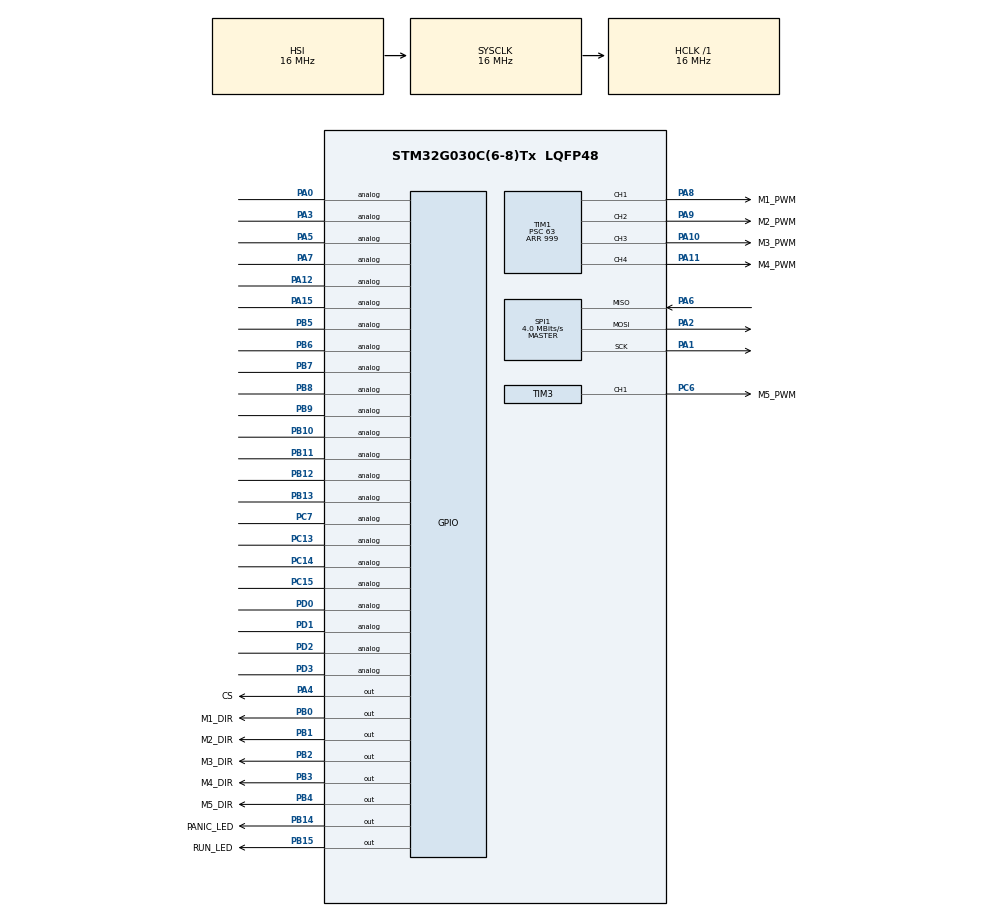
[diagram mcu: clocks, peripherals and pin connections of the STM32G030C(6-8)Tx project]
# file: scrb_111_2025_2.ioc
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Mcu.Family=STM32G0
Mcu.Name=STM32G030C(6-8)Tx
Mcu.Package=LQFP48
PA0.Signal=GPIO_Analog
PA1.Mode=Full_Duplex_Master
PA1.Signal=SPI1_SCK
PA10.GPIO_Label=M3_PWM
PA10.Signal=S_TIM1_CH3
PA11\ [PA9].GPIO_Label=M4_PWM
PA11\ [PA9].Signal=S_TIM1_CH4
PA12\ [PA10].Signal=GPIO_Analog
PA13.Mode=Serial_Wire
PA13.Signal=SYS_SWDIO
PA14-BOOT0.Mode=Serial_Wire
PA14-BOOT0.Signal=SYS_SWCLK
PA15.Signal=GPIO_Analog
PA2.Mode=Full_Duplex_Master
PA2.Signal=SPI1_MOSI
PA3.Signal=GPIO_Analog
PA4.GPIO_Label=CS
PA4.PinState=GPIO_PIN_SET
PA4.Signal=GPIO_Output
PA5.Signal=GPIO_Analog
PA6.Mode=Full_Duplex_Master
PA6.Signal=SPI1_MISO
PA7.Signal=GPIO_Analog
PA8.GPIO_Label=M1_PWM
PA8.Signal=S_TIM1_CH1
PA9.GPIO_Label=M2_PWM
PA9.Signal=S_TIM1_CH2
PB0.GPIO_Label=M1_DIR
PB0.Signal=GPIO_Output
PB1.GPIO_Label=M2_DIR
PB1.Signal=GPIO_Output
PB10.Signal=GPIO_Analog
PB11.Signal=GPIO_Analog
PB12.Signal=GPIO_Analog
PB13.Signal=GPIO_Analog
PB14.GPIO_Label=PANIC_LED
PB14.GPIO_ModeDefaultOutputPP=GPIO_MODE_OUTPUT_OD
PB14.GPIO_PuPd=GPIO_NOPULL
PB14.GPIO_Speed=GPIO_SPEED_FREQ_HIGH
PB14.PinState=GPIO_PIN_RESET
PB14.Signal=GPIO_Output
PB15.GPIO_Label=RUN_LED
PB15.GPIO_ModeDefaultOutputPP=GPIO_MODE_OUTPUT_OD
PB15.GPIO_PuPd=GPIO_NOPULL
PB15.GPIO_Speed=GPIO_SPEED_FREQ_HIGH
PB15.PinState=GPIO_PIN_RESET
PB15.Signal=GPIO_Output
PB2.GPIO_Label=M3_DIR
PB2.Signal=GPIO_Output
PB3.GPIO_Label=M4_DIR
PB3.Signal=GPIO_Output
PB4.GPIO_Label=M5_DIR
PB4.Signal=GPIO_Output
PB5.Signal=GPIO_Analog
PB6.Signal=GPIO_Analog
PB7.Signal=GPIO_Analog
PB8.Signal=GPIO_Analog
PB9.Signal=GPIO_Analog
PC13.Signal=GPIO_Analog
PC14-OSC32_IN\ (PC14).Signal=GPIO_Analog
PC15-OSC32_OUT\ (PC15).Signal=GPIO_Analog
PC6.GPIO_Label=M5_PWM
PC6.Signal=S_TIM3_CH1
PC7.Signal=GPIO_Analog
PD0.Signal=GPIO_Analog
PD1.Signal=GPIO_Analog
PD2.Signal=GPIO_Analog
PD3.Signal=GPIO_Analog
PF0-OSC_IN\ (PF0).Mode=HSE-External-Oscillator
PF0-OSC_IN\ (PF0).Signal=RCC_OSC_IN
PF1-OSC_OUT\ (PF1).Mode=HSE-External-Oscillator
PF1-OSC_OUT\ (PF1).Signal=RCC_OSC_OUT
ProjectManager.HeapSize=0x200
ProjectManager.StackSize=0x400
ProjectManager.TargetToolchain=STM32CubeIDE
RCC.ADCFreq_Value=16000000
RCC.AHBFreq_Value=16000000
RCC.CortexFreq_Value=16000000
RCC.EXTERNAL_CLOCK_VALUE=12288000
RCC.HCLKFreq_Value=16000000
RCC.HSE_VALUE=16000000
RCC.HSI_VALUE=16000000
RCC.LSE_VALUE=32768
RCC.SYSCLKFreq_VALUE=16000000
RCC.VCOOutputFreq_Value=128000000
SH.S_TIM1_CH1.0=TIM1_CH1,PWM Generation1 CH1
SH.S_TIM1_CH2.0=TIM1_CH2,PWM Generation2 CH2
SH.S_TIM1_CH3.0=TIM1_CH3,PWM Generation3 CH3
SH.S_TIM1_CH4.0=TIM1_CH4,PWM Generation4 CH4
SH.S_TIM3_CH1.0=TIM3_CH1,PWM Generation1 CH1
SPI1.BaudRatePrescaler=SPI_BAUDRATEPRESCALER_4
SPI1.CalculateBaudRate=4.0 MBits/s
SPI1.Direction=SPI_DIRECTION_2LINES
SPI1.Mode=SPI_MODE_MASTER
SPI1.VirtualType=VM_MASTER
TIM1.AutomaticOutput=TIM_AUTOMATICOUTPUT_ENABLE
TIM1.Channel-PWM\ Generation1\ CH1=TIM_CHANNEL_1
TIM1.Channel-PWM\ Generation2\ CH2=TIM_CHANNEL_2
TIM1.Channel-PWM\ Generation3\ CH3=TIM_CHANNEL_3
TIM1.Channel-PWM\ Generation4\ CH4=TIM_CHANNEL_4
TIM1.Period=999
TIM1.Prescaler=63
TIM3.Channel-PWM\ Generation1\ CH1=TIM_CHANNEL_1
TIM3.Period=999
TIM3.Prescaler=63
VP_IWDG_VS_IWDG.Mode=IWDG_Activate
VP_TIM1_VS_ClockSourceINT.Mode=Internal
VP_TIM3_VS_ClockSourceINT.Mode=Internal
board=custom

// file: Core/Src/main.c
/* USER CODE BEGIN Header */
/**
  ******************************************************************************
  * @file           : main.c
  * @brief          : Main program body
  ******************************************************************************
  * @attention
  *
  * Copyright (c) 2026 STMicroelectronics.
  * All rights reserved.
  *
  * This software is licensed under terms that can be found in the LICENSE file
  * in the root directory of this software component.
  * If no LICENSE file comes with this software, it is provided AS-IS.
  *
  ******************************************************************************
  */
/* USER CODE END Header */
#include "main.h"
#include "mcp25625.h"
#include "protocol.h"
#include <string.h>
#include <math.h>

IWDG_HandleTypeDef hiwdg;

SPI_HandleTypeDef hspi1;

TIM_HandleTypeDef htim1;
TIM_HandleTypeDef htim3;

void SystemClock_Config(void);
static void MX_GPIO_Init(void);
static void MX_IWDG_Init(void);
static void MX_SPI1_Init(void);
static void MX_TIM1_Init(void);
static void MX_TIM3_Init(void);

int main(void)
{

  /* MCU Configuration--------------------------------------------------------*/

  /* Reset of all peripherals, Initializes the Flash interface and the Systick. */
  HAL_Init();

  /* Configure the system clock */
  SystemClock_Config();

  /* Initialize all configured peripherals */
  MX_GPIO_Init();
  MX_IWDG_Init();
  MX_SPI1_Init();
  MX_TIM1_Init();
  MX_TIM3_Init();
  /* USER CODE BEGIN 2 */

  // starting up the timers for the pwm for each motor
  CanFrame frame = {0};

  start_motors();

  MCP_attach(&hspi1, CS_GPIO_Port, CS_Pin);
  if (!MCP_init()) {
      Error_Handler();
  }

  /* USER CODE END 2 */

  /* Infinite loop */
  /* USER CODE BEGIN WHILE */
  while (1)   {

      HAL_IWDG_Refresh(&hiwdg);
      HAL_GPIO_WritePin(GPIOB, PANIC_LED_Pin, GPIO_PIN_SET);

      if (MCP_receive_frame(&frame))
      {
          uint8_t device_id   = (frame.id >> 1)  & 0x3F;
          uint8_t instruction = (frame.id >> 7)  & 0xFF;
          uint8_t severity    = (frame.id >> 15) & 0x03;

          if (device_id == BOARD_DEVICE_ID && severity == ctrl_id_type)
          {
              if (instruction == force_stop_id_bit) {
                  stop_motors();

                  CanFrame hb_frame = {0};
                  hb_frame.id  = JETSON_MAKE_ID(status_id_type, error_id_bit);
                  hb_frame.dlc = 4;
                  hb_frame.data[0] = 'E';
                  hb_frame.data[1] = '0';
                  hb_frame.data[2] = '7';
                  hb_frame.data[3] = '0';

                  while (1) {
                      HAL_IWDG_Refresh(&hiwdg);
                      MCP_send_frame(&hb_frame);
                      HAL_Delay(100);

                      CanFrame rx = {0};
                      if (MCP_receive_frame(&rx)) {
                          uint8_t rx_dev = (rx.id >> 1)  & 0x3F;
                          uint8_t rx_ins = (rx.id >> 7)  & 0xFF;
                          uint8_t rx_sev = (rx.id >> 15) & 0x03;
                          if (rx_dev == BOARD_DEVICE_ID
                              && rx_sev == ctrl_id_type
                              && rx_ins == resume_id_bit) {
                              start_motors();
                              break;
                          }
                      }
                  }
              }
              else if (instruction == motor_1_id_bit) {
                  float rads;
                  memcpy(&rads, &frame.data[0], 4);
                  uint16_t duty = (fabsf(rads) / MAX_RADS) * htim1.Init.Period;
                  if (duty > htim1.Init.Period) duty = htim1.Init.Period;
                  __HAL_TIM_SET_COMPARE(&htim1, TIM_CHANNEL_1, duty);
                  HAL_GPIO_WritePin(GPIOB, M1_DIR_Pin,
                      rads >= 0.0f ? GPIO_PIN_SET : GPIO_PIN_RESET);

              }
              else if (instruction == motor_2_id_bit) {
                  float rads;
                  memcpy(&rads, &frame.data[0], 4);
                  uint16_t duty = (fabsf(rads) / MAX_RADS) * htim1.Init.Period;
                  if (duty > htim1.Init.Period) duty = htim1.Init.Period;
                  __HAL_TIM_SET_COMPARE(&htim1, TIM_CHANNEL_2, duty);
                  HAL_GPIO_WritePin(GPIOB, M2_DIR_Pin,
                      rads >= 0.0f ? GPIO_PIN_SET : GPIO_PIN_RESET);
              }
              else if (instruction == motor_3_id_bit) {
                  float rads;
                  memcpy(&rads, &frame.data[0], 4);
                  uint16_t duty = (fabsf(rads) / MAX_RADS) * htim1.Init.Period;
                  if (duty > htim1.Init.Period) duty = htim1.Init.Period;
                  __HAL_TIM_SET_COMPARE(&htim1, TIM_CHANNEL_3, duty);
                  HAL_GPIO_WritePin(GPIOB, M3_DIR_Pin,
                      rads >= 0.0f ? GPIO_PIN_SET : GPIO_PIN_RESET);
              }
              else if (instruction == motor_4_id_bit) {
                  float rads;
                  memcpy(&rads, &frame.data[0], 4);
                  uint16_t duty = (fabsf(rads) / MAX_RADS) * htim1.Init.Period;
                  if (duty > htim1.Init.Period) duty = htim1.Init.Period;
                  __HAL_TIM_SET_COMPARE(&htim1, TIM_CHANNEL_4, duty);
                  HAL_GPIO_WritePin(GPIOB, M4_DIR_Pin,
                      rads >= 0.0f ? GPIO_PIN_SET : GPIO_PIN_RESET);
              }
              else if (instruction == motor_5_id_bit) {
                  float rads;
                  memcpy(&rads, &frame.data[0], 4);
                  uint16_t duty = (fabsf(rads) / MAX_RADS) * htim3.Init.Period;
                  if (duty > htim3.Init.Period) duty = htim3.Init.Period;
                  __HAL_TIM_SET_COMPARE(&htim3, TIM_CHANNEL_1, duty);
                  HAL_GPIO_WritePin(GPIOB, M5_DIR_Pin,
                      rads >= 0.0f ? GPIO_PIN_SET : GPIO_PIN_RESET);
              }

          }
      }

      uint8_t eflg = MCP_read_eflg();

      if (eflg & (MCP_EFLG_RX1OVR | MCP_EFLG_RX0OVR)) {

          MCP_clear_rx_overflow();

          HAL_GPIO_WritePin(GPIOB, PANIC_LED_Pin, GPIO_PIN_RESET);

      }

      if (eflg & MCP_EFLG_TXBO) {

          HAL_GPIO_WritePin(GPIOB, PANIC_LED_Pin, GPIO_PIN_RESET);

      }

  }
  /* USER CODE END 3 */
}

void SystemClock_Config(void)
{
  RCC_OscInitTypeDef RCC_OscInitStruct = {0};
  RCC_ClkInitTypeDef RCC_ClkInitStruct = {0};

  /** Configure the main internal regulator output voltage
  */
  HAL_PWREx_ControlVoltageScaling(PWR_REGULATOR_VOLTAGE_SCALE1);

  /** Initializes the RCC Oscillators according to the specified parameters
  * in the RCC_OscInitTypeDef structure.
  */
  RCC_OscInitStruct.OscillatorType = RCC_OSCILLATORTYPE_HSI|RCC_OSCILLATORTYPE_LSI;
  RCC_OscInitStruct.HSIState = RCC_HSI_ON;
  RCC_OscInitStruct.HSIDiv = RCC_HSI_DIV1;
  RCC_OscInitStruct.HSICalibrationValue = RCC_HSICALIBRATION_DEFAULT;
  RCC_OscInitStruct.LSIState = RCC_LSI_ON;
  RCC_OscInitStruct.PLL.PLLState = RCC_PLL_NONE;
  if (HAL_RCC_OscConfig(&RCC_OscInitStruct) != HAL_OK)
  {
    Error_Handler();
  }

  /** Initializes the CPU, AHB and APB buses clocks
  */
  RCC_ClkInitStruct.ClockType = RCC_CLOCKTYPE_HCLK|RCC_CLOCKTYPE_SYSCLK
                              |RCC_CLOCKTYPE_PCLK1;
  RCC_ClkInitStruct.SYSCLKSource = RCC_SYSCLKSOURCE_HSI;
  RCC_ClkInitStruct.AHBCLKDivider = RCC_SYSCLK_DIV1;
  RCC_ClkInitStruct.APB1CLKDivider = RCC_HCLK_DIV1;

  if (HAL_RCC_ClockConfig(&RCC_ClkInitStruct, FLASH_LATENCY_0) != HAL_OK)
  {
    Error_Handler();
  }
}

static void MX_IWDG_Init(void)
{

  hiwdg.Instance = IWDG;
  hiwdg.Init.Prescaler = IWDG_PRESCALER_4;
  hiwdg.Init.Window = 4095;
  hiwdg.Init.Reload = 4095;
  if (HAL_IWDG_Init(&hiwdg) != HAL_OK)
  {
    Error_Handler();
  }

}

static void MX_SPI1_Init(void)
{

  /* SPI1 parameter configuration*/
  hspi1.Instance = SPI1;
  hspi1.Init.Mode = SPI_MODE_MASTER;
  hspi1.Init.Direction = SPI_DIRECTION_2LINES;
  hspi1.Init.DataSize = SPI_DATASIZE_8BIT;
  hspi1.Init.CLKPolarity = SPI_POLARITY_LOW;
  hspi1.Init.CLKPhase = SPI_PHASE_1EDGE;
  hspi1.Init.NSS = SPI_NSS_SOFT;
  hspi1.Init.BaudRatePrescaler = SPI_BAUDRATEPRESCALER_4;
  hspi1.Init.FirstBit = SPI_FIRSTBIT_MSB;
  hspi1.Init.TIMode = SPI_TIMODE_DISABLE;
  hspi1.Init.CRCCalculation = SPI_CRCCALCULATION_DISABLE;
  hspi1.Init.CRCPolynomial = 7;
  hspi1.Init.CRCLength = SPI_CRC_LENGTH_DATASIZE;
  hspi1.Init.NSSPMode = SPI_NSS_PULSE_ENABLE;
  if (HAL_SPI_Init(&hspi1) != HAL_OK)
  {
    Error_Handler();
  }

}

static void MX_TIM1_Init(void)
{

  TIM_ClockConfigTypeDef sClockSourceConfig = {0};
  TIM_MasterConfigTypeDef sMasterConfig = {0};
  TIM_OC_InitTypeDef sConfigOC = {0};
  TIM_BreakDeadTimeConfigTypeDef sBreakDeadTimeConfig = {0};

  htim1.Instance = TIM1;
  htim1.Init.Prescaler = 1;
  htim1.Init.CounterMode = TIM_COUNTERMODE_UP;
  htim1.Init.Period = 799;
  htim1.Init.ClockDivision = TIM_CLOCKDIVISION_DIV1;
  htim1.Init.RepetitionCounter = 0;
  htim1.Init.AutoReloadPreload = TIM_AUTORELOAD_PRELOAD_DISABLE;
  if (HAL_TIM_Base_Init(&htim1) != HAL_OK)
  {
    Error_Handler();
  }
  sClockSourceConfig.ClockSource = TIM_CLOCKSOURCE_INTERNAL;
  if (HAL_TIM_ConfigClockSource(&htim1, &sClockSourceConfig) != HAL_OK)
  {
    Error_Handler();
  }
  if (HAL_TIM_PWM_Init(&htim1) != HAL_OK)
  {
    Error_Handler();
  }
  sMasterConfig.MasterOutputTrigger = TIM_TRGO_RESET;
  sMasterConfig.MasterOutputTrigger2 = TIM_TRGO2_RESET;
  sMasterConfig.MasterSlaveMode = TIM_MASTERSLAVEMODE_DISABLE;
  if (HAL_TIMEx_MasterConfigSynchronization(&htim1, &sMasterConfig) != HAL_OK)
  {
    Error_Handler();
  }
  sConfigOC.OCMode = TIM_OCMODE_PWM1;
  sConfigOC.Pulse = 0;
  sConfigOC.OCPolarity = TIM_OCPOLARITY_HIGH;
  sConfigOC.OCNPolarity = TIM_OCNPOLARITY_HIGH;
  sConfigOC.OCFastMode = TIM_OCFAST_DISABLE;
  sConfigOC.OCIdleState = TIM_OCIDLESTATE_RESET;
  sConfigOC.OCNIdleState = TIM_OCNIDLESTATE_RESET;
  if (HAL_TIM_PWM_ConfigChannel(&htim1, &sConfigOC, TIM_CHANNEL_1) != HAL_OK)
  {
    Error_Handler();
  }
  if (HAL_TIM_PWM_ConfigChannel(&htim1, &sConfigOC, TIM_CHANNEL_2) != HAL_OK)
  {
    Error_Handler();
  }
  if (HAL_TIM_PWM_ConfigChannel(&htim1, &sConfigOC, TIM_CHANNEL_3) != HAL_OK)
  {
    Error_Handler();
  }
  if (HAL_TIM_PWM_ConfigChannel(&htim1, &sConfigOC, TIM_CHANNEL_4) != HAL_OK)
  {
    Error_Handler();
  }
  sBreakDeadTimeConfig.OffStateRunMode = TIM_OSSR_DISABLE;
  sBreakDeadTimeConfig.OffStateIDLEMode = TIM_OSSI_DISABLE;
  sBreakDeadTimeConfig.LockLevel = TIM_LOCKLEVEL_OFF;
  sBreakDeadTimeConfig.DeadTime = 0;
  sBreakDeadTimeConfig.BreakState = TIM_BREAK_DISABLE;
  sBreakDeadTimeConfig.BreakPolarity = TIM_BREAKPOLARITY_HIGH;
  sBreakDeadTimeConfig.BreakFilter = 0;
  sBreakDeadTimeConfig.BreakAFMode = TIM_BREAK_AFMODE_INPUT;
  sBreakDeadTimeConfig.Break2State = TIM_BREAK2_DISABLE;
  sBreakDeadTimeConfig.Break2Polarity = TIM_BREAK2POLARITY_HIGH;
  sBreakDeadTimeConfig.Break2Filter = 0;
  sBreakDeadTimeConfig.Break2AFMode = TIM_BREAK_AFMODE_INPUT;
  sBreakDeadTimeConfig.AutomaticOutput = TIM_AUTOMATICOUTPUT_ENABLE;
  if (HAL_TIMEx_ConfigBreakDeadTime(&htim1, &sBreakDeadTimeConfig) != HAL_OK)
  {
    Error_Handler();
  }
  HAL_TIM_MspPostInit(&htim1);

}

static void MX_TIM3_Init(void)
{

  TIM_ClockConfigTypeDef sClockSourceConfig = {0};
  TIM_MasterConfigTypeDef sMasterConfig = {0};
  TIM_OC_InitTypeDef sConfigOC = {0};

  htim3.Instance = TIM3;
  htim3.Init.Prescaler = 1;
  htim3.Init.CounterMode = TIM_COUNTERMODE_UP;
  htim3.Init.Period = 799;
  htim3.Init.ClockDivision = TIM_CLOCKDIVISION_DIV1;
  htim3.Init.AutoReloadPreload = TIM_AUTORELOAD_PRELOAD_DISABLE;
  if (HAL_TIM_Base_Init(&htim3) != HAL_OK)
  {
    Error_Handler();
  }
  sClockSourceConfig.ClockSource = TIM_CLOCKSOURCE_INTERNAL;
  if (HAL_TIM_ConfigClockSource(&htim3, &sClockSourceConfig) != HAL_OK)
  {
    Error_Handler();
  }
  if (HAL_TIM_PWM_Init(&htim3) != HAL_OK)
  {
    Error_Handler();
  }
  sMasterConfig.MasterOutputTrigger = TIM_TRGO_RESET;
  sMasterConfig.MasterSlaveMode = TIM_MASTERSLAVEMODE_DISABLE;
  if (HAL_TIMEx_MasterConfigSynchronization(&htim3, &sMasterConfig) != HAL_OK)
  {
    Error_Handler();
  }
  sConfigOC.OCMode = TIM_OCMODE_PWM1;
  sConfigOC.Pulse = 0;
  sConfigOC.OCPolarity = TIM_OCPOLARITY_HIGH;
  sConfigOC.OCFastMode = TIM_OCFAST_DISABLE;
  if (HAL_TIM_PWM_ConfigChannel(&htim3, &sConfigOC, TIM_CHANNEL_1) != HAL_OK)
  {
    Error_Handler();
  }
  HAL_TIM_MspPostInit(&htim3);

}

static void MX_GPIO_Init(void)
{
  GPIO_InitTypeDef GPIO_InitStruct = {0};

  /* GPIO Ports Clock Enable */
  __HAL_RCC_GPIOC_CLK_ENABLE();
  __HAL_RCC_GPIOF_CLK_ENABLE();
  __HAL_RCC_GPIOA_CLK_ENABLE();
  __HAL_RCC_GPIOB_CLK_ENABLE();
  __HAL_RCC_GPIOD_CLK_ENABLE();

  /*Configure GPIO pin Output Level */
  HAL_GPIO_WritePin(CS_GPIO_Port, CS_Pin, GPIO_PIN_SET);

  /*Configure GPIO pin Output Level */
  HAL_GPIO_WritePin(GPIOB, M1_DIR_Pin|M2_DIR_Pin|M3_DIR_Pin|PANIC_LED_Pin
                          |RUN_LED_Pin|M4_DIR_Pin|M5_DIR_Pin, GPIO_PIN_RESET);

  /*Configure GPIO pins : PC13 PC14 PC15 PC7 */
  GPIO_InitStruct.Pin = GPIO_PIN_13|GPIO_PIN_14|GPIO_PIN_15|GPIO_PIN_7;
  GPIO_InitStruct.Mode = GPIO_MODE_ANALOG;
  GPIO_InitStruct.Pull = GPIO_NOPULL;
  HAL_GPIO_Init(GPIOC, &GPIO_InitStruct);

  /*Configure GPIO pins : PA0 PA3 PA5 PA7
                           PA12 PA15 */
  GPIO_InitStruct.Pin = GPIO_PIN_0|GPIO_PIN_3|GPIO_PIN_5|GPIO_PIN_7
                          |GPIO_PIN_12|GPIO_PIN_15;
  GPIO_InitStruct.Mode = GPIO_MODE_ANALOG;
  GPIO_InitStruct.Pull = GPIO_NOPULL;
  HAL_GPIO_Init(GPIOA, &GPIO_InitStruct);

  /*Configure GPIO pin : CS_Pin */
  GPIO_InitStruct.Pin = CS_Pin;
  GPIO_InitStruct.Mode = GPIO_MODE_OUTPUT_PP;
  GPIO_InitStruct.Pull = GPIO_NOPULL;
  GPIO_InitStruct.Speed = GPIO_SPEED_FREQ_LOW;
  HAL_GPIO_Init(CS_GPIO_Port, &GPIO_InitStruct);

  /*Configure GPIO pins : M1_DIR_Pin M2_DIR_Pin M3_DIR_Pin M4_DIR_Pin
                           M5_DIR_Pin */
  GPIO_InitStruct.Pin = M1_DIR_Pin|M2_DIR_Pin|M3_DIR_Pin|M4_DIR_Pin
                          |M5_DIR_Pin;
  GPIO_InitStruct.Mode = GPIO_MODE_OUTPUT_PP;
  GPIO_InitStruct.Pull = GPIO_NOPULL;
  GPIO_InitStruct.Speed = GPIO_SPEED_FREQ_LOW;
  HAL_GPIO_Init(GPIOB, &GPIO_InitStruct);

  /*Configure GPIO pins : PB10 PB11 PB12 PB13
                           PB5 PB6 PB7 PB8
                           PB9 */
  GPIO_InitStruct.Pin = GPIO_PIN_10|GPIO_PIN_11|GPIO_PIN_12|GPIO_PIN_13
                          |GPIO_PIN_5|GPIO_PIN_6|GPIO_PIN_7|GPIO_PIN_8
                          |GPIO_PIN_9;
  GPIO_InitStruct.Mode = GPIO_MODE_ANALOG;
  GPIO_InitStruct.Pull = GPIO_NOPULL;
  HAL_GPIO_Init(GPIOB, &GPIO_InitStruct);

  /*Configure GPIO pins : PANIC_LED_Pin RUN_LED_Pin */
  GPIO_InitStruct.Pin = PANIC_LED_Pin|RUN_LED_Pin;
  GPIO_InitStruct.Mode = GPIO_MODE_OUTPUT_OD;
  GPIO_InitStruct.Pull = GPIO_NOPULL;
  GPIO_InitStruct.Speed = GPIO_SPEED_FREQ_HIGH;
  HAL_GPIO_Init(GPIOB, &GPIO_InitStruct);

  /*Configure GPIO pins : PD0 PD1 PD2 PD3 */
  GPIO_InitStruct.Pin = GPIO_PIN_0|GPIO_PIN_1|GPIO_PIN_2|GPIO_PIN_3;
  GPIO_InitStruct.Mode = GPIO_MODE_ANALOG;
  GPIO_InitStruct.Pull = GPIO_NOPULL;
  HAL_GPIO_Init(GPIOD, &GPIO_InitStruct);

}

void Error_Handler(void)
{
  __disable_irq();
  while (1)
  {
  }
}
